# iostr912fa register map
Registers are 32-bit, access not given, no defined reset value unless marked. A register's access mark holds for its fields unless they carry their own. Addresses are absolute; registers are grouped by the start of their names; [hi:lo] are bit positions; 'fields as' and 'values as' point back to an identical list.

## UART1
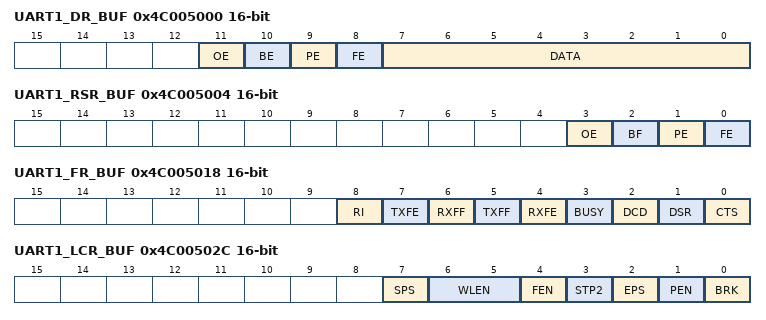
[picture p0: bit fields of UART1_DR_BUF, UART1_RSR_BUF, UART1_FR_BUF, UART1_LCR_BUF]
0x4C005000 UART1_DR_BUF 16-bit
  [11] OE, [10] BE, [9] PE, [8] FE, [7:0] DATA
0x4C005004 UART1_RSR_BUF 16-bit
  [3] OE, [2] BF, [1] PE, [0] FE
0x4C005018 UART1_FR_BUF 16-bit
  [8] RI, [7] TXFE, [6] RXFF, [5] TXFF, [4] RXFE, [3] BUSY, [2] DCD, [1] DSR, [0] CTS
0x4C005020 UART1_ILPR_BUF 8-bit
0x4C005024 UART1_IBRD_BUF 16-bit
0x4C005028 UART1_FBRD_BUF 16-bit
  [5:0] BAUD_DIVFRAC
0x4C00502C UART1_LCR_BUF 16-bit
  [7] SPS, [6:5] WLEN, [4] FEN, [3] STP2, [2] EPS, [1] PEN, [0] BRK
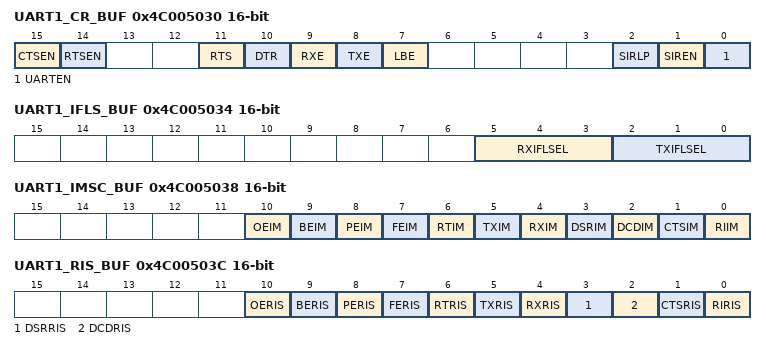
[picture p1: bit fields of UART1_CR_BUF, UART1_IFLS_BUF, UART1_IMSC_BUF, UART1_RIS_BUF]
0x4C005030 UART1_CR_BUF 16-bit
  [15] CTSEN, [14] RTSEN, [11] RTS, [10] DTR, [9] RXE, [8] TXE, [7] LBE, [2] SIRLP, [1] SIREN, [0] UARTEN
0x4C005034 UART1_IFLS_BUF 16-bit
  [5:3] RXIFLSEL, [2:0] TXIFLSEL
0x4C005038 UART1_IMSC_BUF 16-bit
  [10] OEIM, [9] BEIM, [8] PEIM, [7] FEIM, [6] RTIM, [5] TXIM, [4] RXIM, [3] DSRIM, [2] DCDIM, [1] CTSIM, [0] RIIM
0x4C00503C UART1_RIS_BUF 16-bit
  [10] OERIS, [9] BERIS, [8] PERIS, [7] FERIS, [6] RTRIS, [5] TXRIS, [4] RXRIS, [3] DSRRIS, [2] DCDRIS, [1] CTSRIS, [0] RIRIS
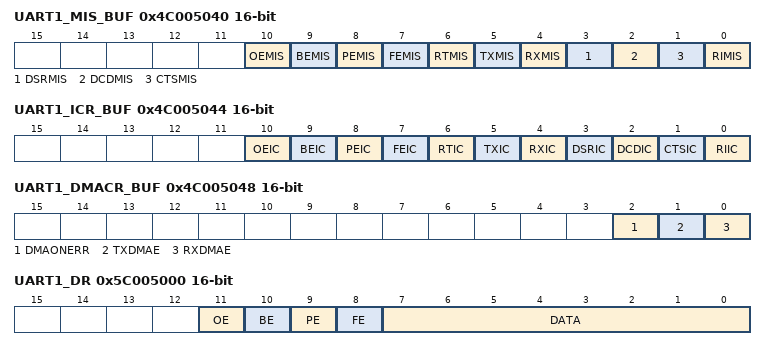
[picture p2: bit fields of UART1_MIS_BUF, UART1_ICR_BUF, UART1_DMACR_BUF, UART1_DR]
0x4C005040 UART1_MIS_BUF 16-bit
  [10] OEMIS, [9] BEMIS, [8] PEMIS, [7] FEMIS, [6] RTMIS, [5] TXMIS, [4] RXMIS, [3] DSRMIS, [2] DCDMIS, [1] CTSMIS, [0] RIMIS
0x4C005044 UART1_ICR_BUF 16-bit
  [10] OEIC, [9] BEIC, [8] PEIC, [7] FEIC, [6] RTIC, [5] TXIC, [4] RXIC, [3] DSRIC, [2] DCDIC, [1] CTSIC, [0] RIIC
0x4C005048 UART1_DMACR_BUF 16-bit
  [2] DMAONERR, [1] TXDMAE, [0] RXDMAE
0x5C005000 UART1_DR 16-bit
  [11] OE, [10] BE, [9] PE, [8] FE, [7:0] DATA
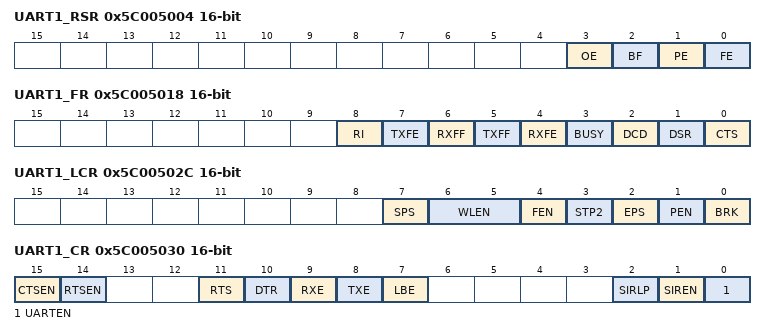
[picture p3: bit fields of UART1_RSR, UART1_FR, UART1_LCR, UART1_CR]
0x5C005004 UART1_RSR 16-bit
  [3] OE, [2] BF, [1] PE, [0] FE
0x5C005018 UART1_FR 16-bit
  fields as UART1_FR_BUF
0x5C005020 UART1_ILPR 8-bit
0x5C005024 UART1_IBRD 16-bit
0x5C005028 UART1_FBRD 16-bit
  [5:0] BAUD_DIVFRAC
0x5C00502C UART1_LCR 16-bit
  [7] SPS, [6:5] WLEN, [4] FEN, [3] STP2, [2] EPS, [1] PEN, [0] BRK
0x5C005030 UART1_CR 16-bit
  fields as UART1_CR_BUF
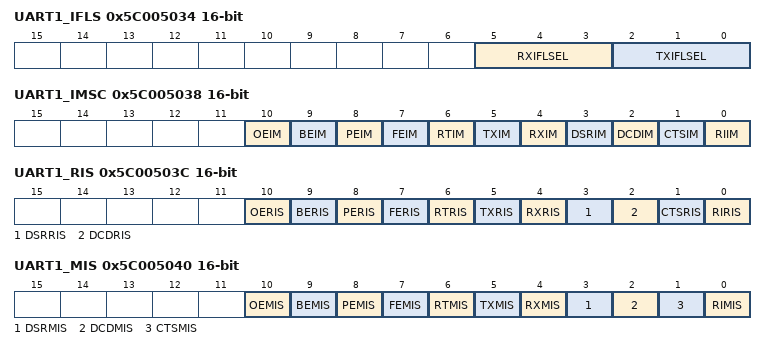
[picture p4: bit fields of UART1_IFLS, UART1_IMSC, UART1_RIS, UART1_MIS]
0x5C005034 UART1_IFLS 16-bit
  [5:3] RXIFLSEL, [2:0] TXIFLSEL
0x5C005038 UART1_IMSC 16-bit
  fields as UART1_IMSC_BUF
0x5C00503C UART1_RIS 16-bit
  fields as UART1_RIS_BUF
0x5C005040 UART1_MIS 16-bit
  fields as UART1_MIS_BUF
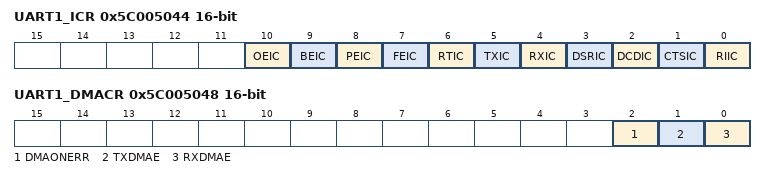
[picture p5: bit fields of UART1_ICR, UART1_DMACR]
0x5C005044 UART1_ICR 16-bit
  fields as UART1_ICR_BUF
0x5C005048 UART1_DMACR 16-bit
  [2] DMAONERR, [1] TXDMAE, [0] RXDMAE

## UART2
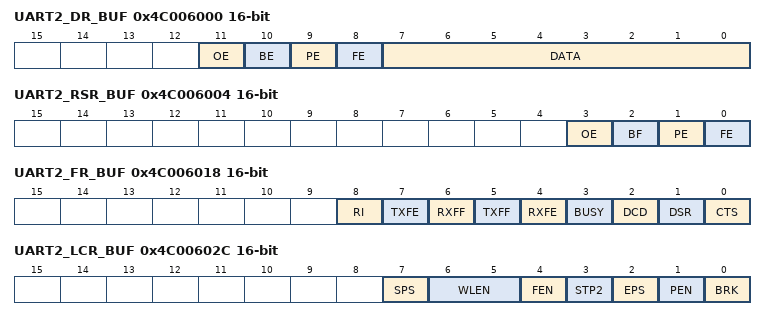
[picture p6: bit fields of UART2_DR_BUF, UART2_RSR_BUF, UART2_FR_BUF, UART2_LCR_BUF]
0x4C006000 UART2_DR_BUF 16-bit
  [11] OE, [10] BE, [9] PE, [8] FE, [7:0] DATA
0x4C006004 UART2_RSR_BUF 16-bit
  [3] OE, [2] BF, [1] PE, [0] FE
0x4C006018 UART2_FR_BUF 16-bit
  [8] RI, [7] TXFE, [6] RXFF, [5] TXFF, [4] RXFE, [3] BUSY, [2] DCD, [1] DSR, [0] CTS
0x4C006020 UART2_ILPR_BUF 8-bit
0x4C006024 UART2_IBRD_BUF 16-bit
0x4C006028 UART2_FBRD_BUF 16-bit
  [5:0] BAUD_DIVFRAC
0x4C00602C UART2_LCR_BUF 16-bit
  [7] SPS, [6:5] WLEN, [4] FEN, [3] STP2, [2] EPS, [1] PEN, [0] BRK
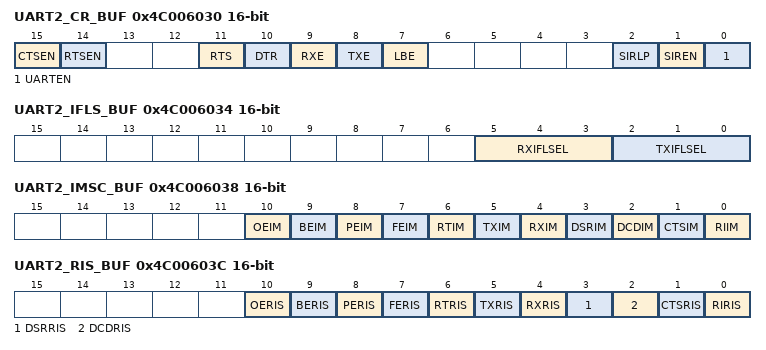
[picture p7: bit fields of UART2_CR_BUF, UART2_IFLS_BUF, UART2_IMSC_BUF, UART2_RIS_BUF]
0x4C006030 UART2_CR_BUF 16-bit
  [15] CTSEN, [14] RTSEN, [11] RTS, [10] DTR, [9] RXE, [8] TXE, [7] LBE, [2] SIRLP, [1] SIREN, [0] UARTEN
0x4C006034 UART2_IFLS_BUF 16-bit
  [5:3] RXIFLSEL, [2:0] TXIFLSEL
0x4C006038 UART2_IMSC_BUF 16-bit
  [10] OEIM, [9] BEIM, [8] PEIM, [7] FEIM, [6] RTIM, [5] TXIM, [4] RXIM, [3] DSRIM, [2] DCDIM, [1] CTSIM, [0] RIIM
0x4C00603C UART2_RIS_BUF 16-bit
  [10] OERIS, [9] BERIS, [8] PERIS, [7] FERIS, [6] RTRIS, [5] TXRIS, [4] RXRIS, [3] DSRRIS, [2] DCDRIS, [1] CTSRIS, [0] RIRIS
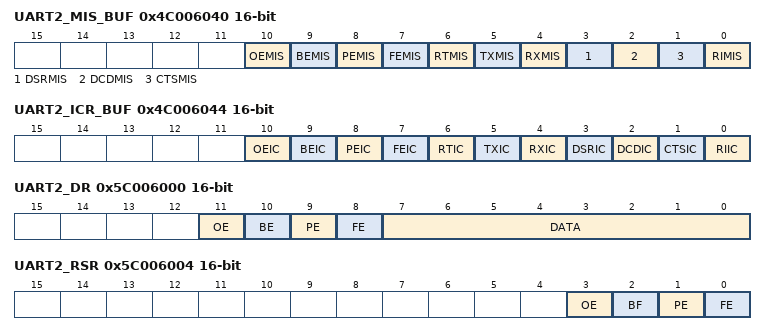
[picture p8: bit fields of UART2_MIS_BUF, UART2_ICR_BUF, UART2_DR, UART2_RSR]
0x4C006040 UART2_MIS_BUF 16-bit
  [10] OEMIS, [9] BEMIS, [8] PEMIS, [7] FEMIS, [6] RTMIS, [5] TXMIS, [4] RXMIS, [3] DSRMIS, [2] DCDMIS, [1] CTSMIS, [0] RIMIS
0x4C006044 UART2_ICR_BUF 16-bit
  [10] OEIC, [9] BEIC, [8] PEIC, [7] FEIC, [6] RTIC, [5] TXIC, [4] RXIC, [3] DSRIC, [2] DCDIC, [1] CTSIC, [0] RIIC
0x5C006000 UART2_DR 16-bit
  [11] OE, [10] BE, [9] PE, [8] FE, [7:0] DATA
0x5C006004 UART2_RSR 16-bit
  [3] OE, [2] BF, [1] PE, [0] FE
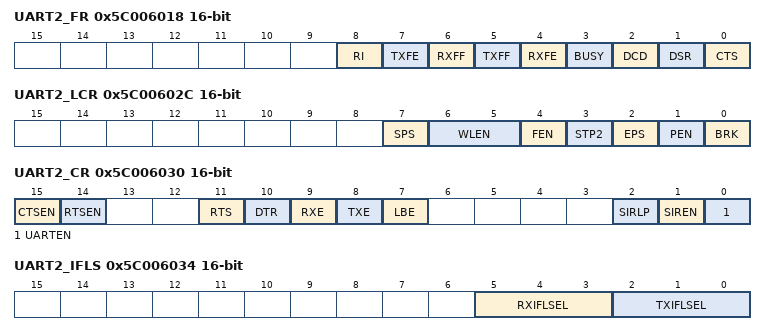
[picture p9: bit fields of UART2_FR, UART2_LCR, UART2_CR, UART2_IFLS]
0x5C006018 UART2_FR 16-bit
  fields as UART2_FR_BUF
0x5C006020 UART2_ILPR 8-bit
0x5C006024 UART2_IBRD 16-bit
0x5C006028 UART2_FBRD 16-bit
  [5:0] BAUD_DIVFRAC
0x5C00602C UART2_LCR 16-bit
  [7] SPS, [6:5] WLEN, [4] FEN, [3] STP2, [2] EPS, [1] PEN, [0] BRK
0x5C006030 UART2_CR 16-bit
  fields as UART2_CR_BUF
0x5C006034 UART2_IFLS 16-bit
  [5:3] RXIFLSEL, [2:0] TXIFLSEL
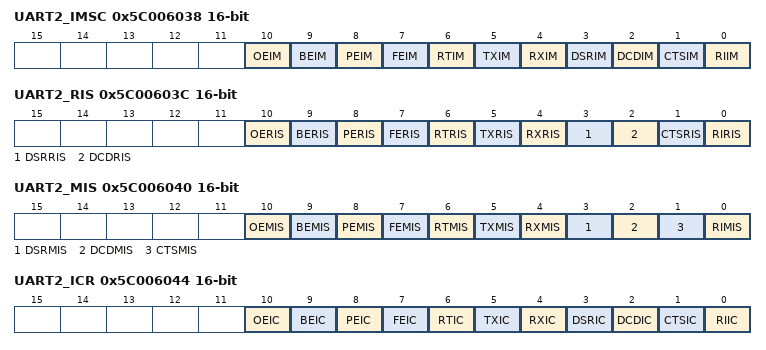
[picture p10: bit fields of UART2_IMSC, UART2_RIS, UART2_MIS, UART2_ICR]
0x5C006038 UART2_IMSC 16-bit
  fields as UART2_IMSC_BUF
0x5C00603C UART2_RIS 16-bit
  fields as UART2_RIS_BUF
0x5C006040 UART2_MIS 16-bit
  fields as UART2_MIS_BUF
0x5C006044 UART2_ICR 16-bit
  fields as UART2_ICR_BUF
